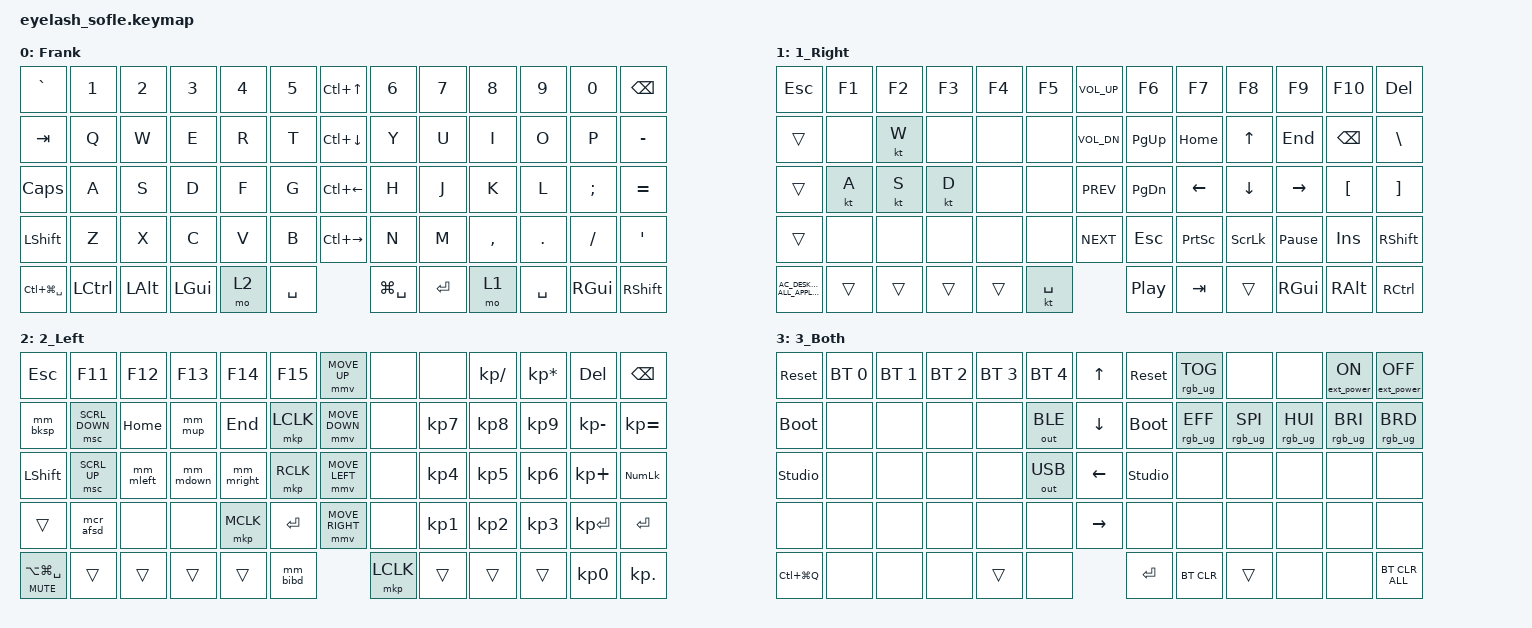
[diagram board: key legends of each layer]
#define ZMK_POINTING_DEFAULT_MOVE_VAL 1200  // 600
#define ZMK_POINTING_DEFAULT_SCRL_VAL 25   // 10

#include <input/processors.dtsi>
#include <zephyr/dt-bindings/input/input-event-codes.h>
#include <behaviors.dtsi>
#include <dt-bindings/zmk/bt.h>
#include <dt-bindings/zmk/ext_power.h>
#include <dt-bindings/zmk/keys.h>
#include <dt-bindings/zmk/pointing.h>
#include <dt-bindings/zmk/rgb.h>
#include <dt-bindings/zmk/outputs.h>

&mmv_input_listener { input-processors = <&zip_xy_scaler 2 1>; };
&msc_input_listener { input-processors = <&zip_scroll_scaler 2 1>; };

&msc {
    acceleration-exponent = <0>;      // 0
    time-to-max-speed-ms = <0>;       // 300
    delay-ms = <0>;                   // 0
};

&mmv {
    time-to-max-speed-ms = <200>;
    acceleration-exponent = <1>;
    trigger-period-ms = <16>;
};

/ {
    scroll_encoder: scroll_encoder {
        compatible = "zmk,behavior-sensor-rotate";
        #sensor-binding-cells = <0>;
        bindings = <&msc SCRL_UP>, <&msc SCRL_DOWN>;
        tap-ms = <80>;
    };
    conditional_layers {
        compatible = "zmk,conditional-layers";
        combo_layer {
            if-layers = <1 2>;
            then-layer = <3>;
        };
    };
    behaviors {
        mm_brace: mod_morph_brace {
            compatible = "zmk,behavior-mod-morph";
            #binding-cells = <0>;
            bindings = <&kp LBRC>, <&kp RBRC>;
            mods = <(MOD_LSFT | MOD_RSFT)>; };
        mm_up: mod_morph_up {
            compatible = "zmk,behavior-mod-morph";
            #binding-cells = <0>;
            bindings = <&kp UP>, <&kp PAGE_UP>;
            mods = <(MOD_LSFT | MOD_RSFT)>; };
        mm_down: mod_morph_down {
            compatible = "zmk,behavior-mod-morph";
            #binding-cells = <0>;
            bindings = <&kp DOWN>, <&kp PAGE_DOWN>;
            mods = <(MOD_LSFT | MOD_RSFT)>; };
        mm_left: mod_morph_left {
            compatible = "zmk,behavior-mod-morph";
            #binding-cells = <0>;
            bindings = <&kp LEFT>, <&kp HOME>;
            mods = <(MOD_LSFT | MOD_RSFT)>; };
        mm_right: mod_morph_right {
            compatible = "zmk,behavior-mod-morph";
            #binding-cells = <0>;
            bindings = <&kp RIGHT>, <&kp END>;
            mods = <(MOD_LSFT | MOD_RSFT)>; };
        mm_mup: mod_morph_mouse_up {
            compatible = "zmk,behavior-mod-morph";
            #binding-cells = <0>;
            bindings = <&kp UP>, <&mmv MOVE_UP>;
            mods = <(MOD_LSFT | MOD_RSFT)>;
            keep-mods = <0>; };
        mm_mdown: mod_morph_mouse_down {
            compatible = "zmk,behavior-mod-morph";
            #binding-cells = <0>;
            bindings = <&kp DOWN>, <&mmv MOVE_DOWN>;
            mods = <(MOD_LSFT | MOD_RSFT)>;
            keep-mods = <0>; };
        mm_mleft: mod_morph_mouse_left {
            compatible = "zmk,behavior-mod-morph";
            #binding-cells = <0>;
            bindings = <&kp LEFT>, <&mmv MOVE_LEFT>;
            mods = <(MOD_LSFT | MOD_RSFT)>;
            keep-mods = <0>; };
        mm_mright: mod_morph_mouse_right {
            compatible = "zmk,behavior-mod-morph";
            #binding-cells = <0>;
            bindings = <&kp RIGHT>, <&mmv MOVE_RIGHT>;
            mods = <(MOD_LSFT | MOD_RSFT)>;
            keep-mods = <0>; };
        mm_bksp: mod_morph_backspace {
            compatible = "zmk,behavior-mod-morph";
            #binding-cells = <0>;
            bindings = <&kp BACKSPACE>, <&kp DELETE>;
            mods = <(MOD_LSFT | MOD_RSFT)>; };
        mm_bibd: mod_morph_brightness {
            compatible = "zmk,behavior-mod-morph";
            #binding-cells = <0>;
            bindings = <&kp C_BRI_INC>, <&kp C_BRI_DEC>;
            mods = <(MOD_LSFT | MOD_RSFT)>; };
    };
    macros {
        mcr_afsd: macro_afsdafsd {
            compatible = "zmk,behavior-macro";
            #binding-cells = <0>;
            tap-ms = <100>;
            bindings = <
                &kp A &kp F &kp S &kp D &kp A &kp F &kp S &kp D
            >;
        };
    };
    keymap {
        compatible = "zmk,keymap";
        layer0 { bindings = <
&kp GRAVE	&kp N1		&kp N2		&kp N3		&kp N4		&kp N5				&kp LC(UP)					&kp N6		&kp N7		&kp N8		&kp N9		&kp N0		&kp BACKSPACE
&kp TAB		&kp Q		&kp W		&kp E		&kp R		&kp T				&kp LC(DOWN)				&kp Y		&kp U		&kp I		&kp O		&kp P		&kp MINUS
&kp CAPS	&kp A		&kp S		&kp D		&kp F		&kp G				&kp LC(LEFT)				&kp H		&kp J		&kp K		&kp L		&kp SEMI	&kp EQUAL
&kp LSHFT	&kp Z		&kp X		&kp C		&kp V		&kp B				&kp LC(RIGHT)				&kp N		&kp M		&kp COMMA	&kp DOT		&kp FSLH	&kp APOS
&kp LC(LG(SPACE))		&kp LCTRL	&kp LALT	&kp LGUI	&mo 2	&kp SPACE	&kp LG(SPACE)	&kp ENTER	&mo 1		&kp SPACE	&kp RGUI	&kp RSHIFT
				>; sensor-bindings = <&scroll_encoder>;							display-name = "Frank";
        };
        layer_1 { bindings = <
&kp ESC		&kp F1		&kp F2		&kp F3		&kp F4		&kp F5				&kp C_VOL_UP				&kp F6		&kp F7		&kp F8		&kp F9		&kp F10		&kp DELETE
&trans		&none		&kt W		&none		&none		&none				&kp C_VOL_DN				&kp PG_UP	&kp HOME	&kp UP		&kp END		&kp BACKSPACE&kp BSLH
&trans		&kt A		&kt S		&kt D		&none		&none				&kp C_PREV					&kp PG_DN	&kp LEFT	&kp DOWN	&kp RIGHT	&kp LBKT	&kp RBKT
&trans		&none		&none		&none		&none		&none				&kp C_NEXT					&kp ESC		&kp PSCRN	&kp SLCK	&kp PAUSE_BREAK&kp INSERT&kp RSHIFT
&kp C_AC_DESKTOP_SHOW_ALL_APPLICATIONS &trans &trans &trans	&trans	&kt SPACE	&kp C_PP		&kp TAB		&trans		&kp RGUI	&kp RALT	&kp RCTRL
				>; sensor-bindings = <&inc_dec_kp C_BRI_INC C_BRI_DEC>;			display-name = "1_Right";
        };
        layer_2 { bindings = <
&kp ESC		&kp F11		&kp F12		&kp F13		&kp F14		&kp F15				&mmv MOVE_UP				&none		&none		&kp KP_SLASH&kp KP_ASTERISK&kp DELETE&kp BACKSPACE
&mm_bksp	&msc SCRL_DOWN&kp HOME	&mm_mup		&kp END		&mkp LCLK			&mmv MOVE_DOWN				&none		&kp KP_N7	&kp KP_N8	&kp KP_N9	&kp KP_MINUS&kp KP_EQUAL
&kp LSHFT	&msc SCRL_UP&mm_mleft	&mm_mdown	&mm_mright	&mkp RCLK			&mmv MOVE_LEFT				&none		&kp KP_N4	&kp KP_N5	&kp KP_N6	&kp KP_PLUS	&kp KP_NUMLOCK
&trans		&mcr_afsd	&none		&none		&mkp MCLK	&kp ENTER			&mmv MOVE_RIGHT				&none		&kp KP_N1	&kp KP_N2	&kp KP_N3	&kp KP_ENTER&kp ENTER
&mt C_MUTE LA(LG(SPACE))&trans		&trans		&trans		&trans	&mm_bibd	&mkp LCLK		&trans		&trans		&trans		&kp KP_N0	&kp KP_DOT
				>; sensor-bindings = <&inc_dec_kp C_VOL_UP C_VOL_DN>;			display-name = "2_Left";
        };
        layer_3 { bindings = <
&sys_reset	&bt BT_SEL 0 &bt BT_SEL 1 &bt BT_SEL 2 &bt BT_SEL 3	&bt BT_SEL 4	&kp UP						&sys_reset	&rgb_ug RGB_TOG	&none	&none &ext_power EP_ON	&ext_power EP_OFF
&bootloader	&none		&none		&none		&none		&out OUT_BLE		&kp DOWN					&bootloader	&rgb_ug RGB_EFF &rgb_ug RGB_SPI &rgb_ug RGB_HUI &rgb_ug RGB_BRI &rgb_ug RGB_BRD
&studio_unlock &none	&none		&none		&none		&out OUT_USB		&kp LEFT					&studio_unlock &none	&none		&none		&none		&none
&none		&none		&none		&none		&none		&none				&kp RIGHT					&none		&none		&none		&none		&none		&none
&kp LC(LG(Q))			&none		&none		&none		&trans	&none		&kp ENTER		 &bt BT_CLR &trans		&none		&none		&bt BT_CLR_ALL
                >; sensor-bindings = <&inc_dec_kp RIGHT LEFT>;					display-name = "3_Both";
        };
    };
};
